# R7FA2T107 register map
Vendor: Renesas Electronics Corporation; Series: RA2; File version: 1.00.00
CPU: CM23 r1p0, little endian, MPU, no FPU, VTOR, 2 interrupt priority bits, 32 interrupts
Registers are 8-bit, read-write, reset 0x0 unless marked. A register's access mark holds for its fields unless they carry their own. Offsets are from the block's base; [hi:lo] are bit positions; {n}, {i} and the like mark numbered series; 'fields as' and 'values as' point back to an identical list.

## ELC — Event Link Controller
Base 0x40041000
0x00 ELCR — Event Link Controller Register
  [7] ELCON — All Event Link Enable
    0=ELC function is disabled; 1=ELC function is enabled
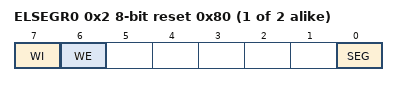
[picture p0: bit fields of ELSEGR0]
{0x2+2i} ELSEGR{i} (i=0..1) reset 0x80 — Event Link Software Event Generation Register {i}
  [7] WI wo — ELSEGR Register Write Disable
    0=Write to ELSEGR register enabled; 1=Write to ELSEGR register disabled
  [6] WE — SEG Bit Write Enable
    0=Write to SEG bit disabled; 1=Write to SEG bit enabled
  [0] SEG wo — Software Event Generation
    0=Normal operation; 1=Software event is generated
{0x10+4i} ELSR{i} (i=0..9) 16-bit — Event Link Setting Register {i}
  [7:0] ELS — Event Link Select
{0x10+4i} ELSR{i} (i=14..15) 16-bit — Event Link Setting Register {i}
  [7:0] ELS — Event Link Select

## POEG — Port Output Enable Module for GPT
Base 0x40042000
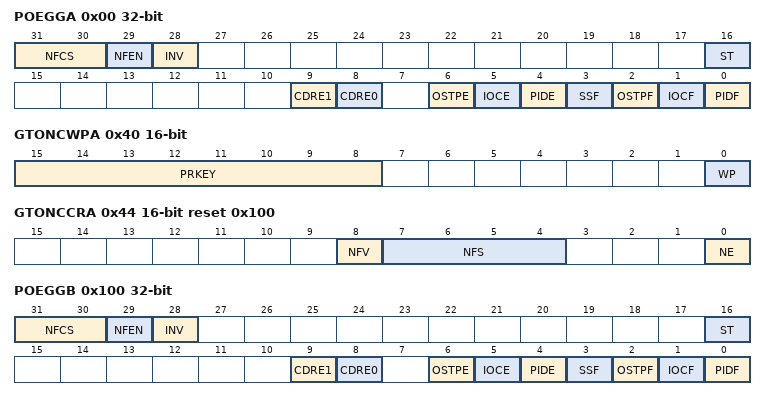
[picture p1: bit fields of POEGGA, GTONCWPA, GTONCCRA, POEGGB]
0x00 POEGGA 32-bit — POEG Group A Setting Register
  [31:30] NFCS — Noise filter Clock Select
    0=Samples the input level of GTETRGn pin three times per PCLKB/1 clock; 1=Samples the input level of GTETRGn pin three times per PCLKB/8 clock; 2=Samples the input level of GTETRGn pin three times per PCLKB/32 clock; 3=Samples the input level of GTETRGn pin three times per PCLKB/128 clock
  [29] NFEN — Noise filter Enable
    0=Digital noise filter on the GTETRGn pin is disabled; 1=Digital noise filter on the GTETRGn pin is enabled
  [28] INV — GTETRGn Input Inverting
    0=Input on the GTETRGn pin is not inverted; 1=Input on the GTETRGn pin is inverted
  [16] ST ro — GTETRGn Input Status Flag
    0=The corresponding external trigger for output to the GPT is 0; 1=The corresponding external trigger for output to the GPT is 1
  [9] CDRE1 — ACMPHS1 Enable
    0=Comparator edge detection 1 is disabled; 1=Comparator edge detection 1 is enabled
  [8] CDRE0 — ACMPHS0 Enable
    0=Comparator edge detection 0 is disabled; 1=Comparator edge detection 0 is enabled
  [6] OSTPE — Enable Stopping Output on Stopping of Oscillation
    0=Detection of stopping of oscillation is disabled; 1=Detection of stopping of oscillation is enabled
  [5] IOCE — GPT Output Stop Request Enable
    0=Detection of stopping of output from the GPT is disabled; 1=Detection of stopping of output from the GPT is enabled
  [4] PIDE — Port Input Detection Enable
    0=Detection of input levels on the corresponding GTETRGn pin is disabled; 1=Detection of input levels on the corresponding GTETRGn pin is enabled
  [3] SSF — Software Stop Flag
    0=Software has not stopped output; 1=Software has stopped output
  [2] OSTPF — Oscillation Stop Detection Flag
    0=Stopping of oscillation was not detected; 1=Stopping of oscillation was detected
  [1] IOCF — GPT or ACMPHS Output Stop Request Detection Flag
    0=Neither stopping of GPT output nor a comparator edge was detected; 1=Either stopping of GPT output or comparator edge was detected
  [0] PIDF — Port Input Detection Flag
    0=The selected input level was not detected on the GTETRGn pin; 1=The selected input level was detected on the GTETRGn pin
0x40 GTONCWPA 16-bit — GPT Output Stopping Control Group A Write Protection Register
  [15:8] PRKEY — Key Code
  [0] WP — Register Writing Disable
    0=Writing to the GTONCCRn register is enabled; 1=Writing to the GTONCCRn register is disabled
0x44 GTONCCRA 16-bit reset 0x100 — GPT Output Stopping Control Group A Controlling Register
  [8] NFV — Direct Stopping Request Active Sense
    0=Stopping output is requested when the output stopping detection signal is 0; 1=Stopping output is requested when the output stopping detection signal is 1
  [7:4] NFS — Direct Stopping Request Selection
    0=Comparator level detection 0; 1=Comparator level detection 1; 7=GTETRGn pin input level detection (n = A, B); other=Others (Setting prohibited)
  [0] NE — Direct Stopping Request Setting
    0=The signal for detection is not set as a direct stopping request signal; 1=The signal for detection is set as a direct stopping request signal
0x100 POEGGB 32-bit — POEG Group B Setting Register
  fields as POEGGA
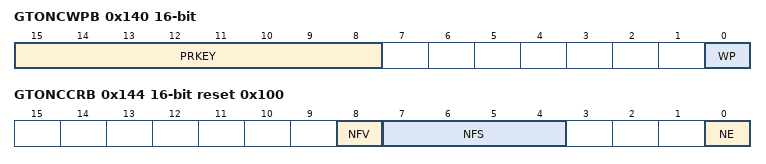
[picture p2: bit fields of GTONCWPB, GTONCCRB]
0x140 GTONCWPB 16-bit — GPT Output Stopping Control Group B Write Protection Register
  fields as GTONCWPA
0x144 GTONCCRB 16-bit reset 0x100 — GPT Output Stopping Control Group B Controlling Register
  fields as GTONCCRA
